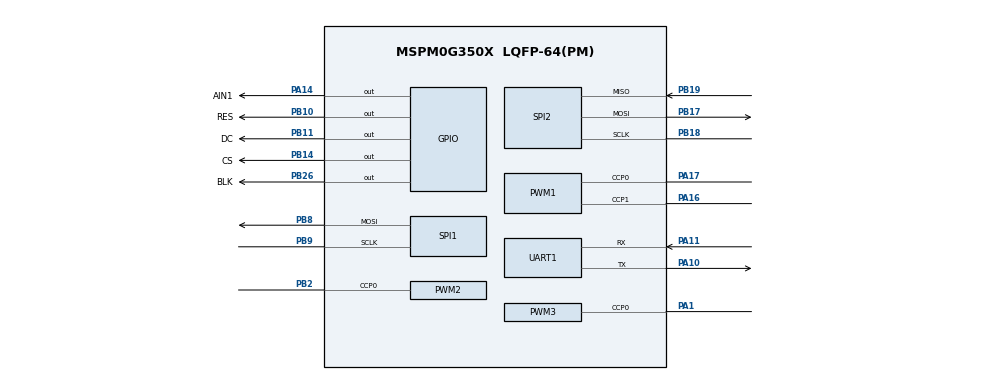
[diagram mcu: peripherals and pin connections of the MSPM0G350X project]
/**
 * @cliArgs --device "MSPM0G350X" --part "Default" --package "LQFP-64(PM)" --product "mspm0_sdk@2.02.00.05"
 * @versions {"tool":"1.21.1+3772"}
 */

/**
 * Import the modules used in this configuration.
 */
const GPIO    = scripting.addModule("/ti/driverlib/GPIO", {}, false);
const GPIO1   = GPIO.addInstance();
const GPIO2   = GPIO.addInstance();
const GPIO3   = GPIO.addInstance();
const GPIO4   = GPIO.addInstance();
const GPIO5   = GPIO.addInstance();
const GPIO6   = GPIO.addInstance();
const PWM     = scripting.addModule("/ti/driverlib/PWM", {}, false);
const PWM1    = PWM.addInstance();
const PWM2    = PWM.addInstance();
const PWM3    = PWM.addInstance();
const SPI     = scripting.addModule("/ti/driverlib/SPI", {}, false);
const SPI1    = SPI.addInstance();
const SPI2    = SPI.addInstance();
const SYSCTL  = scripting.addModule("/ti/driverlib/SYSCTL");
const SYSTICK = scripting.addModule("/ti/driverlib/SYSTICK");
const TIMER   = scripting.addModule("/ti/driverlib/TIMER", {}, false);
const TIMER1  = TIMER.addInstance();
const UART    = scripting.addModule("/ti/driverlib/UART", {}, false);
const UART1   = UART.addInstance();

/**
 * Write custom configuration values to the imported modules.
 */
GPIO1.port                           = "PORTB";
GPIO1.$name                          = "TFT";
GPIO1.associatedPins.create(4);
GPIO1.associatedPins[0].$name        = "RES";
GPIO1.associatedPins[0].ioStructure  = "SD";
GPIO1.associatedPins[0].assignedPin  = "10";
GPIO1.associatedPins[0].pin.$assign  = "PB10";
GPIO1.associatedPins[1].$name        = "DC";
GPIO1.associatedPins[1].assignedPin  = "11";
GPIO1.associatedPins[1].ioStructure  = "SD";
GPIO1.associatedPins[1].pin.$assign  = "PB11";
GPIO1.associatedPins[2].$name        = "CS";
GPIO1.associatedPins[2].assignedPin  = "14";
GPIO1.associatedPins[2].ioStructure  = "SD";
GPIO1.associatedPins[2].initialValue = "SET";
GPIO1.associatedPins[2].pin.$assign  = "PB14";
GPIO1.associatedPins[3].$name        = "BLK";
GPIO1.associatedPins[3].assignedPin  = "26";
GPIO1.associatedPins[3].ioStructure  = "SD";
GPIO1.associatedPins[3].initialValue = "SET";
GPIO1.associatedPins[3].pin.$assign  = "PB26";

const Board = scripting.addModule("/ti/driverlib/Board", {}, false);

GPIO2.$name                               = "ENCODER";
GPIO2.port                                = "PORTB";
GPIO2.associatedPins.create(4);
GPIO2.associatedPins[0].direction         = "INPUT";
GPIO2.associatedPins[0].interruptEn       = true;
GPIO2.associatedPins[0].polarity          = "RISE_FALL";
GPIO2.associatedPins[0].$name             = "LA";
GPIO2.associatedPins[0].assignedPin       = "15";
GPIO2.associatedPins[0].interruptPriority = "0";
GPIO2.associatedPins[1].direction         = "INPUT";
GPIO2.associatedPins[1].$name             = "LB";
GPIO2.associatedPins[1].interruptEn       = true;
GPIO2.associatedPins[1].polarity          = "RISE_FALL";
GPIO2.associatedPins[1].assignedPin       = "16";
GPIO2.associatedPins[1].interruptPriority = "0";
GPIO2.associatedPins[2].direction         = "INPUT";
GPIO2.associatedPins[2].$name             = "RA";
GPIO2.associatedPins[2].interruptEn       = true;
GPIO2.associatedPins[2].polarity          = "RISE_FALL";
GPIO2.associatedPins[2].assignedPin       = "06";
GPIO2.associatedPins[2].interruptPriority = "0";
GPIO2.associatedPins[3].direction         = "INPUT";
GPIO2.associatedPins[3].$name             = "RB";
GPIO2.associatedPins[3].interruptEn       = true;
GPIO2.associatedPins[3].polarity          = "RISE_FALL";
GPIO2.associatedPins[3].assignedPin       = "07";
GPIO2.associatedPins[3].interruptPriority = "0";

GPIO3.port                           = "PORTA";
GPIO3.$name                          = "TB6612_A";
GPIO3.associatedPins.create(2);
GPIO3.associatedPins[0].$name        = "AIN1";
GPIO3.associatedPins[0].initialValue = "SET";
GPIO3.associatedPins[0].assignedPin  = "14";
GPIO3.associatedPins[0].pin.$assign  = "PA14";
GPIO3.associatedPins[1].$name        = "AIN2";
GPIO3.associatedPins[1].initialValue = "SET";
GPIO3.associatedPins[1].assignedPin  = "15";

GPIO4.$name                          = "TB6612_B";
GPIO4.port                           = "PORTB";
GPIO4.associatedPins.create(2);
GPIO4.associatedPins[0].$name        = "BIN1";
GPIO4.associatedPins[0].assignedPin  = "12";
GPIO4.associatedPins[0].initialValue = "SET";
GPIO4.associatedPins[1].$name        = "BIN2";
GPIO4.associatedPins[1].assignedPin  = "13";

GPIO5.$name                              = "LDC";
GPIO5.associatedPins.create(2);
GPIO5.associatedPins[0].$name            = "CSB";
GPIO5.associatedPins[0].assignedPort     = "PORTA";
GPIO5.associatedPins[0].assignedPin      = "08";
GPIO5.associatedPins[0].initialValue     = "SET";
GPIO5.associatedPins[1].$name            = "INTB";
GPIO5.associatedPins[1].direction        = "INPUT";
GPIO5.associatedPins[1].assignedPort     = "PORTB";
GPIO5.associatedPins[1].assignedPin      = "03";
GPIO5.associatedPins[1].internalResistor = "PULL_UP";

GPIO6.$name                          = "BUZZER";
GPIO6.associatedPins[0].assignedPort = "PORTB";
GPIO6.associatedPins[0].assignedPin  = "27";
GPIO6.associatedPins[0].$name        = "IO";
GPIO6.associatedPins[0].initialValue = "SET";

PWM1.timerStartTimer                    = true;
PWM1.timerCount                         = 100;
PWM1.clockDivider                       = 8;
PWM1.clockPrescale                      = 4;
PWM1.$name                              = "TB6612_PWM";
PWM1.pwmMode                            = "EDGE_ALIGN_UP";
PWM1.peripheral.$assign                 = "TIMA1";
PWM1.peripheral.ccp0Pin.$assign         = "PA17";
PWM1.peripheral.ccp1Pin.$assign         = "PA16";
PWM1.PWM_CHANNEL_0.$name                = "ti_driverlib_pwm_PWMTimerCC0";
PWM1.PWM_CHANNEL_1.$name                = "ti_driverlib_pwm_PWMTimerCC1";
PWM1.ccp0PinConfig.direction            = scripting.forceWrite("OUTPUT");
PWM1.ccp0PinConfig.hideOutputInversion  = scripting.forceWrite(false);
PWM1.ccp0PinConfig.onlyInternalResistor = scripting.forceWrite(false);
PWM1.ccp0PinConfig.passedPeripheralType = scripting.forceWrite("Digital");
PWM1.ccp0PinConfig.$name                = "ti_driverlib_gpio_GPIOPinGeneric5";
PWM1.ccp1PinConfig.direction            = scripting.forceWrite("OUTPUT");
PWM1.ccp1PinConfig.hideOutputInversion  = scripting.forceWrite(false);
PWM1.ccp1PinConfig.onlyInternalResistor = scripting.forceWrite(false);
PWM1.ccp1PinConfig.passedPeripheralType = scripting.forceWrite("Digital");
PWM1.ccp1PinConfig.$name                = "ti_driverlib_gpio_GPIOPinGeneric6";

PWM2.$name                              = "LDC_CLK";
PWM2.timerStartTimer                    = true;
PWM2.ccIndex                            = [0];
PWM2.timerCount                         = 4;
PWM2.pwmMode                            = "CENTER_ALIGN";
PWM2.peripheral.$assign                 = "TIMG6";
PWM2.peripheral.ccp0Pin.$assign         = "PB2";
PWM2.PWM_CHANNEL_0.$name                = "ti_driverlib_pwm_PWMTimerCC2";
PWM2.PWM_CHANNEL_0.dutyCycle            = 50;
PWM2.ccp0PinConfig.direction            = scripting.forceWrite("OUTPUT");
PWM2.ccp0PinConfig.hideOutputInversion  = scripting.forceWrite(false);
PWM2.ccp0PinConfig.onlyInternalResistor = scripting.forceWrite(false);
PWM2.ccp0PinConfig.passedPeripheralType = scripting.forceWrite("Digital");
PWM2.ccp0PinConfig.$name                = "ti_driverlib_gpio_GPIOPinGeneric10";

PWM3.$name                              = "SERVO";
PWM3.ccIndex                            = [0];
PWM3.clockDivider                       = 8;
PWM3.pwmMode                            = "EDGE_ALIGN_UP";
PWM3.timerCount                         = 20000;
PWM3.clockPrescale                      = 4;
PWM3.timerStartTimer                    = true;
PWM3.peripheral.$assign                 = "TIMG8";
PWM3.peripheral.ccp0Pin.$assign         = "PA1";
PWM3.PWM_CHANNEL_0.$name                = "ti_driverlib_pwm_PWMTimerCC3";
PWM3.PWM_CHANNEL_0.ccValue              = 1500;
PWM3.ccp0PinConfig.direction            = scripting.forceWrite("OUTPUT");
PWM3.ccp0PinConfig.hideOutputInversion  = scripting.forceWrite(false);
PWM3.ccp0PinConfig.onlyInternalResistor = scripting.forceWrite(false);
PWM3.ccp0PinConfig.passedPeripheralType = scripting.forceWrite("Digital");
PWM3.ccp0PinConfig.$name                = "ti_driverlib_gpio_GPIOPinGeneric11";

SPI1.frameFormat                        = "MOTO3";
SPI1.$name                              = "TFT_SPI";
SPI1.peripheral.$assign                 = "SPI1";
SPI1.peripheral.sclkPin.$assign         = "PB9";
SPI1.peripheral.mosiPin.$assign         = "PB8";
SPI1.sclkPinConfig.direction            = scripting.forceWrite("OUTPUT");
SPI1.sclkPinConfig.onlyInternalResistor = scripting.forceWrite(false);
SPI1.sclkPinConfig.passedPeripheralType = scripting.forceWrite("Digital");
SPI1.sclkPinConfig.$name                = "ti_driverlib_gpio_GPIOPinGeneric0";
SPI1.mosiPinConfig.direction            = scripting.forceWrite("OUTPUT");
SPI1.mosiPinConfig.hideOutputInversion  = scripting.forceWrite(false);
SPI1.mosiPinConfig.onlyInternalResistor = scripting.forceWrite(false);
SPI1.mosiPinConfig.passedPeripheralType = scripting.forceWrite("Digital");
SPI1.mosiPinConfig.$name                = "ti_driverlib_gpio_GPIOPinGeneric1";
SPI1.misoPinConfig.onlyInternalResistor = scripting.forceWrite(false);
SPI1.misoPinConfig.passedPeripheralType = scripting.forceWrite("Digital");
SPI1.misoPinConfig.$name                = "ti_driverlib_gpio_GPIOPinGeneric2";

SPI2.$name                              = "SPI_LDC";
SPI2.frameFormat                        = "MOTO3";
SPI2.polarity                           = "1";
SPI2.phase                              = "1";
SPI2.targetBitRate                      = 1000000;
SPI2.peripheral.sclkPin.$assign         = "PB18";
SPI2.peripheral.mosiPin.$assign         = "PB17";
SPI2.peripheral.misoPin.$assign         = "PB19";
SPI2.sclkPinConfig.direction            = scripting.forceWrite("OUTPUT");
SPI2.sclkPinConfig.onlyInternalResistor = scripting.forceWrite(false);
SPI2.sclkPinConfig.passedPeripheralType = scripting.forceWrite("Digital");
SPI2.sclkPinConfig.$name                = "ti_driverlib_gpio_GPIOPinGeneric7";
SPI2.mosiPinConfig.direction            = scripting.forceWrite("OUTPUT");
SPI2.mosiPinConfig.hideOutputInversion  = scripting.forceWrite(false);
SPI2.mosiPinConfig.onlyInternalResistor = scripting.forceWrite(false);
SPI2.mosiPinConfig.passedPeripheralType = scripting.forceWrite("Digital");
SPI2.mosiPinConfig.$name                = "ti_driverlib_gpio_GPIOPinGeneric8";
SPI2.misoPinConfig.onlyInternalResistor = scripting.forceWrite(false);
SPI2.misoPinConfig.passedPeripheralType = scripting.forceWrite("Digital");
SPI2.misoPinConfig.$name                = "ti_driverlib_gpio_GPIOPinGeneric9";

SYSCTL.forceDefaultClkConfig = true;
SYSCTL.clockTreeEn           = true;

SYSTICK.periodEnable      = true;
SYSTICK.period            = 32000;
SYSTICK.interruptEnable   = true;
SYSTICK.systickEnable     = true;
SYSTICK.interruptPriority = "1";

TIMER1.$name              = "TIMER_0";
TIMER1.timerClkDiv        = 8;
TIMER1.timerClkPrescale   = 40;
TIMER1.timerPeriod        = "10ms";
TIMER1.timerStartTimer    = true;
TIMER1.interrupts         = ["ZERO"];
TIMER1.timerMode          = "PERIODIC";
TIMER1.interruptPriority  = "2";
TIMER1.peripheral.$assign = "TIMG0";

UART1.$name                    = "UART_0";
UART1.peripheral.rxPin.$assign = "PA11";
UART1.peripheral.txPin.$assign = "PA10";
UART1.txPinConfig.$name        = "ti_driverlib_gpio_GPIOPinGeneric3";
UART1.rxPinConfig.$name        = "ti_driverlib_gpio_GPIOPinGeneric4";

/**
 * Pinmux solution for unlocked pins/peripherals. This ensures that minor changes to the automatic solver in a future
 * version of the tool will not impact the pinmux you originally saw.  These lines can be completely deleted in order to
 * re-solve from scratch.
 */
Board.peripheral.$suggestSolution            = "DEBUGSS";
Board.peripheral.swclkPin.$suggestSolution   = "PA20";
Board.peripheral.swdioPin.$suggestSolution   = "PA19";
GPIO2.associatedPins[0].pin.$suggestSolution = "PB15";
GPIO2.associatedPins[1].pin.$suggestSolution = "PB16";
GPIO2.associatedPins[2].pin.$suggestSolution = "PB6";
GPIO2.associatedPins[3].pin.$suggestSolution = "PB7";
GPIO3.associatedPins[1].pin.$suggestSolution = "PA15";
GPIO4.associatedPins[0].pin.$suggestSolution = "PB12";
GPIO4.associatedPins[1].pin.$suggestSolution = "PB13";
GPIO5.associatedPins[0].pin.$suggestSolution = "PA8";
GPIO5.associatedPins[1].pin.$suggestSolution = "PB3";
GPIO6.associatedPins[0].pin.$suggestSolution = "PB27";
SPI1.peripheral.misoPin.$suggestSolution     = "PB21";
SPI2.peripheral.$suggestSolution             = "SPI0";
UART1.peripheral.$suggestSolution            = "UART0";
